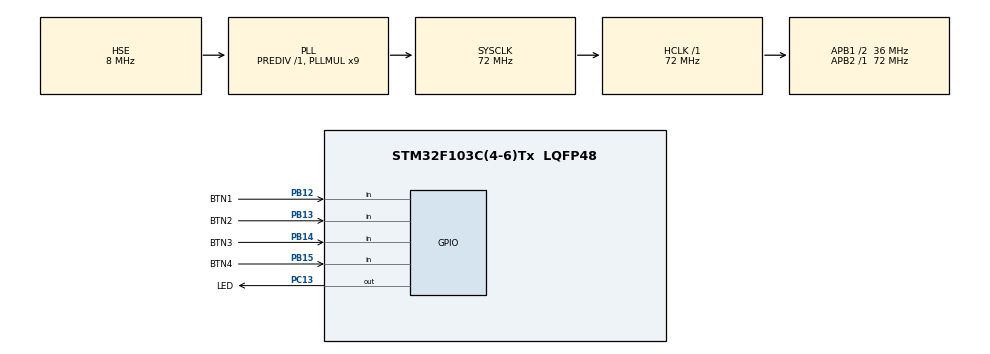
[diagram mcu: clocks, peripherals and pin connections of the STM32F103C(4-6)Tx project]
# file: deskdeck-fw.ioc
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<<<<<<< HEAD
=======
>>>>>>> feat/gpio-led-button
Mcu.Family=STM32F1
<<<<<<< HEAD
=======
>>>>>>> feat/gpio-led-button
Mcu.Name=STM32F103C(4-6)Tx
Mcu.Package=LQFP48
<<<<<<< HEAD
=======
>>>>>>> feat/gpio-led-button
NVIC.PriorityGroup=NVIC_PRIORITYGROUP_4
<<<<<<< HEAD
NVIC.TIM2_IRQn=true\:0\:0\:false\:false\:true\:true\:true\:true
=======
>>>>>>> feat/gpio-led-button
PA13.Mode=Serial_Wire
PA13.Signal=SYS_JTMS-SWDIO
PA14.Mode=Serial_Wire
PA14.Signal=SYS_JTCK-SWCLK
PB12.GPIO_Label=BTN1
PB12.GPIO_PuPd=GPIO_PULLUP
PB12.Signal=GPIO_Input
PB13.GPIO_Label=BTN2
PB13.GPIO_PuPd=GPIO_PULLUP
PB13.Signal=GPIO_Input
<<<<<<< HEAD
PB14.GPIO_Label=BTN3
PB14.GPIO_PuPd=GPIO_PULLUP
PB14.Signal=GPIO_Input
PB15.GPIO_Label=BTN4
PB15.GPIO_PuPd=GPIO_PULLUP
PB15.Signal=GPIO_Input
PC13-TAMPER-RTC.GPIO_Label=LED
PC13-TAMPER-RTC.GPIO_PuPd=GPIO_NOPULL
=======
PC13-TAMPER-RTC.GPIO_Label=LED
>>>>>>> feat/gpio-led-button
PC13-TAMPER-RTC.Signal=GPIO_Output
PD0-OSC_IN.Mode=HSE-External-Oscillator
PD0-OSC_IN.Signal=RCC_OSC_IN
PD1-OSC_OUT.Mode=HSE-External-Oscillator
PD1-OSC_OUT.Signal=RCC_OSC_OUT
ProjectManager.HeapSize=0x200
ProjectManager.StackSize=0x400
ProjectManager.TargetToolchain=STM32CubeIDE
RCC.AHBFreq_Value=72000000
RCC.APB1CLKDivider=RCC_HCLK_DIV2
RCC.APB1Freq_Value=36000000
RCC.APB1TimFreq_Value=72000000
RCC.APB2Freq_Value=72000000
RCC.APB2TimFreq_Value=72000000
RCC.HCLKFreq_Value=72000000
RCC.PLLMUL=RCC_PLL_MUL9
RCC.PLLSourceVirtual=RCC_PLLSOURCE_HSE
RCC.SYSCLKFreq_VALUE=72000000
RCC.SYSCLKSource=RCC_SYSCLKSOURCE_PLLCLK
RCC.USBFreq_Value=72000000
<<<<<<< HEAD
TIM2.Prescaler=71
VP_TIM2_VS_ClockSourceINT.Mode=Internal
=======
>>>>>>> feat/gpio-led-button
board=custom

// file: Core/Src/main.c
/* USER CODE BEGIN Header */
/**
  ******************************************************************************
  * @file           : main.c
  * @brief          : Main program body
  ******************************************************************************
  * @attention
  *
  * Copyright (c) 2026 STMicroelectronics.
  * All rights reserved.
  *
  * This software is licensed under terms that can be found in the LICENSE file
  * in the root directory of this software component.
  * If no LICENSE file comes with this software, it is provided AS-IS.
  *
  ******************************************************************************
  */
/* USER CODE END Header */
#include "main.h"
<<<<<<< HEAD
#include "tim.h"
=======
>>>>>>> feat/gpio-led-button
#include "gpio.h"

void SystemClock_Config(void);

int main(void)
{

  /* MCU Configuration--------------------------------------------------------*/

  /* Reset of all peripherals, Initializes the Flash interface and the Systick. */
  HAL_Init();

  /* Configure the system clock */
  SystemClock_Config();

  /* Initialize all configured peripherals */
  MX_GPIO_Init();
<<<<<<< HEAD
  MX_TIM2_Init();
=======
>>>>>>> feat/gpio-led-button

  /* Infinite loop */
  while (1)
  {

    /* USER CODE BEGIN 3 */
<<<<<<< HEAD
=======
	//  if(HAL_GPIO_ReadPin(BTN1_GPIO_Port,BTN1_Pin)== GPIO_PIN_RESET){
	//	  HAL_GPIO_WritePin(LED_GPIO_Port,LED_Pin, GPIO_PIN_RESET);
	//  }else{
	//	  HAL_GPIO_WritePin(LED_GPIO_Port,LED_Pin, GPIO_PIN_SET);
	//  }
	  if (HAL_GPIO_ReadPin(BTN1_GPIO_Port, BTN1_Pin) == GPIO_PIN_RESET) {
		  HAL_GPIO_WritePin(LED_GPIO_Port,LED_Pin, GPIO_PIN_RESET);
	  }
	  if (HAL_GPIO_ReadPin(BTN2_GPIO_Port, BTN2_Pin) == GPIO_PIN_RESET) {
	 		  HAL_GPIO_WritePin(LED_GPIO_Port,LED_Pin, GPIO_PIN_SET);
	 	  }

>>>>>>> feat/gpio-led-button
  }
  /* USER CODE END 3 */
}

void SystemClock_Config(void)
{
  RCC_OscInitTypeDef RCC_OscInitStruct = {0};
  RCC_ClkInitTypeDef RCC_ClkInitStruct = {0};

  /** Initializes the RCC Oscillators according to the specified parameters
  * in the RCC_OscInitTypeDef structure.
  */
  RCC_OscInitStruct.OscillatorType = RCC_OSCILLATORTYPE_HSE;
  RCC_OscInitStruct.HSEState = RCC_HSE_ON;
  RCC_OscInitStruct.HSEPredivValue = RCC_HSE_PREDIV_DIV1;
  RCC_OscInitStruct.HSIState = RCC_HSI_ON;
  RCC_OscInitStruct.PLL.PLLState = RCC_PLL_ON;
  RCC_OscInitStruct.PLL.PLLSource = RCC_PLLSOURCE_HSE;
  RCC_OscInitStruct.PLL.PLLMUL = RCC_PLL_MUL9;
  if (HAL_RCC_OscConfig(&RCC_OscInitStruct) != HAL_OK)
  {
    Error_Handler();
  }

  /** Initializes the CPU, AHB and APB buses clocks
  */
  RCC_ClkInitStruct.ClockType = RCC_CLOCKTYPE_HCLK|RCC_CLOCKTYPE_SYSCLK
                              |RCC_CLOCKTYPE_PCLK1|RCC_CLOCKTYPE_PCLK2;
  RCC_ClkInitStruct.SYSCLKSource = RCC_SYSCLKSOURCE_PLLCLK;
  RCC_ClkInitStruct.AHBCLKDivider = RCC_SYSCLK_DIV1;
  RCC_ClkInitStruct.APB1CLKDivider = RCC_HCLK_DIV2;
  RCC_ClkInitStruct.APB2CLKDivider = RCC_HCLK_DIV1;

  if (HAL_RCC_ClockConfig(&RCC_ClkInitStruct, FLASH_LATENCY_2) != HAL_OK)
  {
    Error_Handler();
  }
}

void Error_Handler(void)
{
  __disable_irq();
  while (1)
  {
  }
}
